VERSION ""

NS_ :

BS_:

BU_: DSC DME SZL

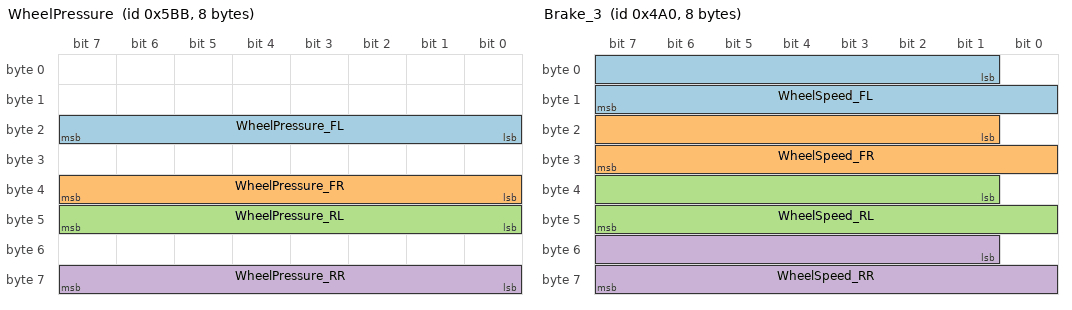
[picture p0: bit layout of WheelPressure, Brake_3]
BO_ 1467 WheelPressure: 8 DSC
 SG_ WheelPressure_FL : 16|8@1+ (1,0) [0|255] "bar" Vector__XXX
 SG_ WheelPressure_FR : 32|8@1+ (1,0) [0|255] "bar" Vector__XXX
 SG_ WheelPressure_RL : 40|8@1+ (1,0) [0|255] "bar" Vector__XXX
 SG_ WheelPressure_RR : 56|8@1+ (1,0) [0|255] "bar" Vector__XXX

BO_ 416 Brake_1: 8 DSC
 SG_ ASR_TrqReductionReq : 0|1@1+ (1,0) [0|1] "" Vector__XXX
 SG_ MSR_TrqIncreaseReq : 1|1@1+ (1,0) [0|1] "" Vector__XXX
 SG_ ABS_Active : 2|1@1+ (1,0) [0|1] "" Vector__XXX
 SG_ TCS_Active : 3|1@1+ (1,0) [0|1] "" Vector__XXX
 SG_ AYC_Active : 4|1@1+ (1,0) [0|1] "" Vector__XXX
 SG_ ASR_ActiveIndicator : 5|2@1+ (1,0) [0|3] "" Vector__XXX
 SG_ ABS_EBV_Running : 7|1@1+ (1,0) [0|1] "" Vector__XXX
 SG_ ABS_WarningLamp : 8|1@1+ (1,0) [0|1] "" Vector__XXX
 SG_ DSC_TCS_Lamp : 9|1@1+ (1,0) [0|1] "" Vector__XXX
 SG_ Brake_EBV_FailLamp : 10|1@1+ (1,0) [0|1] "" Vector__XXX
 SG_ BrakeLightSwitch : 11|1@1+ (1,0) [0|1] "" Vector__XXX
 SG_ DiagSessionBusy : 15|1@1+ (1,0) [0|1] "" Vector__XXX
 SG_ VehicleSpeed : 17|15@1+ (0.01,0) [0|327.67] "km/h" Vector__XXX
 SG_ ASR_TrqTarget : 32|8@1+ (0.39,0) [0|99.45] "%" Vector__XXX
 SG_ ASR_HoldTrq_MSR_Inv : 40|8@1+ (1,0) [0|255] "" Vector__XXX
 SG_ MSR_TrqTarget : 48|8@1+ (0.39,0) [0|99.45] "%" Vector__XXX
 SG_ AliveCounter : 56|4@1+ (1,0) [0|15] "" Vector__XXX
 SG_ DSC_SwitchModeA_0or6 : 61|1@1+ (1,0) [0|1] "" Vector__XXX
 SG_ LatchedFaultPresent : 62|1@1+ (1,0) [0|1] "" Vector__XXX
 SG_ ExtSpeedStatus : 63|1@1+ (1,0) [0|1] "" Vector__XXX

BO_ 428 Brake_8: 8 DSC
 SG_ LongitudinalAccel : 48|10@1+ (0.00408,-2.08896) [-2.08896|2.08488] "g" Vector__XXX

BO_ 1184 Brake_3: 8 DSC
 SG_ WheelSpeed_FL : 1|15@1+ (0.01,0) [0|327.67] "km/h" Vector__XXX
 SG_ WheelSpeed_FR : 17|15@1+ (0.01,0) [0|327.67] "km/h" Vector__XXX
 SG_ WheelSpeed_RL : 33|15@1+ (0.01,0) [0|327.67] "km/h" Vector__XXX
 SG_ WheelSpeed_RR : 49|15@1+ (0.01,0) [0|327.67] "km/h" Vector__XXX

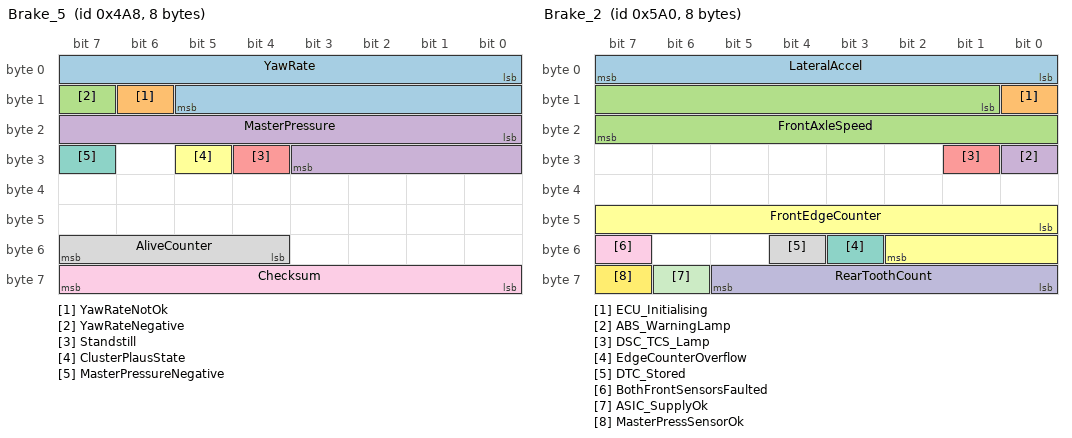
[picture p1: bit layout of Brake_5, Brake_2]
BO_ 1192 Brake_5: 8 DSC
 SG_ YawRate : 0|14@1+ (0.01,0) [0|163.83] "deg/s" Vector__XXX
 SG_ YawRateNotOk : 14|1@1+ (1,0) [0|1] "" Vector__XXX
 SG_ YawRateNegative : 15|1@1+ (1,0) [0|1] "" Vector__XXX
 SG_ MasterPressure : 16|12@1+ (0.1,0) [0|409.5] "bar" Vector__XXX
 SG_ Standstill : 28|1@1+ (1,0) [0|1] "" Vector__XXX
 SG_ ClusterPlausState : 29|1@1+ (1,0) [0|1] "" Vector__XXX
 SG_ MasterPressureNegative : 31|1@1+ (1,0) [0|1] "" Vector__XXX
 SG_ AliveCounter : 52|4@1+ (1,0) [0|15] "" Vector__XXX
 SG_ Checksum : 56|8@1+ (1,0) [0|255] "" Vector__XXX

BO_ 1440 Brake_2: 8 DSC
 SG_ LateralAccel : 0|8@1+ (0.02,-2.54) [-2.54|2.56] "g" Vector__XXX
 SG_ ECU_Initialising : 8|1@1+ (1,0) [0|1] "" Vector__XXX
 SG_ FrontAxleSpeed : 9|15@1+ (0.01,0) [0|327.67] "km/h" Vector__XXX
 SG_ ABS_WarningLamp : 24|1@1+ (1,0) [0|1] "" Vector__XXX
 SG_ DSC_TCS_Lamp : 25|1@1+ (1,0) [0|1] "" Vector__XXX
 SG_ FrontEdgeCounter : 40|11@1+ (1,0) [0|2047] "" Vector__XXX
 SG_ EdgeCounterOverflow : 51|1@1+ (1,0) [0|1] "" Vector__XXX
 SG_ DTC_Stored : 52|1@1+ (1,0) [0|1] "" Vector__XXX
 SG_ BothFrontSensorsFaulted : 55|1@1+ (1,0) [0|1] "" Vector__XXX
 SG_ RearToothCount : 56|6@1+ (1,0) [0|63] "" Vector__XXX
 SG_ ASIC_SupplyOk : 62|1@1+ (1,0) [0|1] "" Vector__XXX
 SG_ MasterPressSensorOk : 63|1@1+ (1,0) [0|1] "" Vector__XXX

BO_ 1696 CCP_DTO: 8 DSC
 SG_ DTO_Data : 0|64@1+ (1,0) [0|1.844674407e+19] "" Vector__XXX

BO_ 1986 Key_7C2: 4 DSC
 SG_ KeyStatusByte : 0|8@1+ (1,0) [0|255] "" Vector__XXX

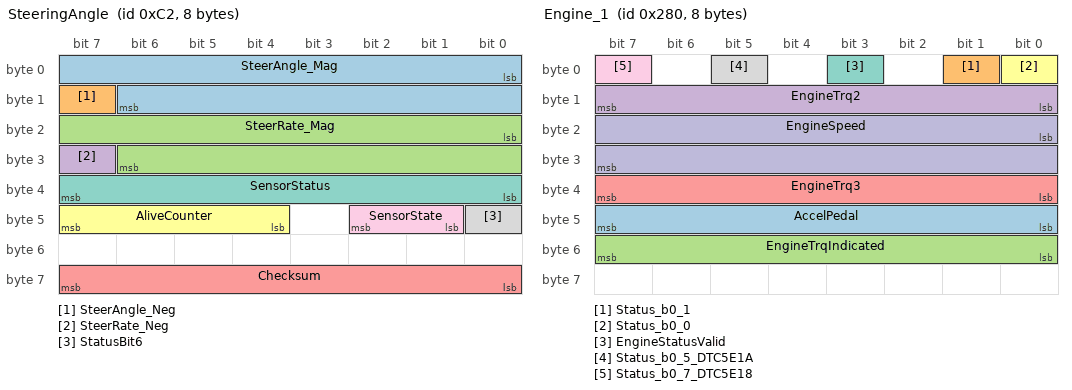
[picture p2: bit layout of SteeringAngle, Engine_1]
BO_ 194 SteeringAngle: 8 SZL
 SG_ SteerAngle_Mag : 0|15@1+ (1,0) [0|32767] "" DSC
 SG_ SteerAngle_Neg : 15|1@1+ (1,0) [0|1] "" DSC
 SG_ SteerRate_Mag : 16|15@1+ (1,0) [0|32767] "" DSC
 SG_ SteerRate_Neg : 31|1@1+ (1,0) [0|1] "" DSC
 SG_ Checksum : 56|8@1+ (1,0) [0|255] "" DSC
 SG_ AliveCounter : 44|4@1+ (1,0) [0|15] "" DSC
 SG_ SensorStatus : 32|8@1+ (1,0) [0|255] "" DSC
 SG_ StatusBit6 : 40|1@1+ (1,0) [0|1] "" DSC
 SG_ SensorState : 41|2@1+ (1,0) [0|3] "" DSC

BO_ 640 Engine_1: 8 DME
 SG_ AccelPedal : 40|8@1+ (1,0) [0|255] "" DSC
 SG_ Status_b0_1 : 1|1@1+ (1,0) [0|1] "" DSC
 SG_ EngineTrqIndicated : 48|8@1+ (1,0) [0|255] "" DSC
 SG_ EngineTrq2 : 8|8@1+ (1,0) [0|255] "" DSC
 SG_ EngineTrq3 : 32|8@1+ (1,0) [0|255] "" DSC
 SG_ Status_b0_0 : 0|1@1+ (1,0) [0|1] "" DSC
 SG_ EngineStatusValid : 3|1@1+ (1,0) [0|1] "" DSC
 SG_ Status_b0_5_DTC5E1A : 5|1@1+ (1,0) [0|1] "" DSC
 SG_ Status_b0_7_DTC5E18 : 7|1@1+ (1,0) [0|1] "" DSC
 SG_ EngineSpeed : 16|16@1+ (0.5,0) [0|32767.5] "rpm" DSC

BO_ 648 Engine_2: 8 DME
 SG_ MaxTrqScale : 0|8@1+ (1,0) [0|255] "" DSC
 SG_ Status_b2_4 : 20|1@1+ (1,0) [0|1] "" DSC

BO_ 704 Diag_2C0: 4 Vector__XXX
 SG_ Byte1_DTC5E58 : 8|8@1+ (1,0) [0|255] "" DSC

BO_ 912 BrakeMode_390: 8 Vector__XXX
 SG_ BrakeMode1 : 50|1@1+ (1,0) [0|1] "" DSC
 SG_ BrakeMode3 : 51|1@1+ (1,0) [0|1] "" DSC

BO_ 1088 Gear_440: 8 Vector__XXX
 SG_ GearSourceFlag : 0|1@1+ (1,0) [0|1] "" DSC
 SG_ GearCode : 8|4@1+ (1,0) [0|15] "" DSC

BO_ 1152 Engine_3: 8 DME
 SG_ TrqScaleMultiplierSel : 51|1@1+ (1,0) [0|1] "" DSC

BO_ 1312 Odometer_520: 8 Vector__XXX
 SG_ Value14_Mode2 : 0|16@1+ (1,0) [0|65535] "" DSC
 SG_ Odometer : 40|20@1+ (1,0) [0|1048575] "" DSC

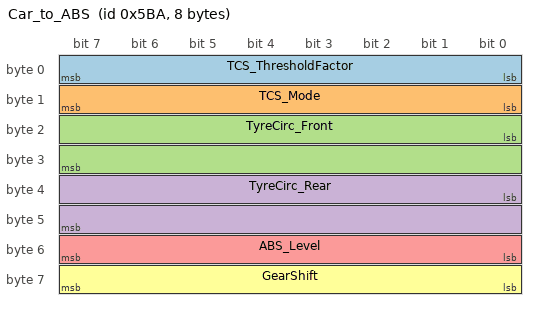
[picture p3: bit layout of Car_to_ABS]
BO_ 1466 Car_to_ABS: 8 Vector__XXX
 SG_ TCS_ThresholdFactor : 0|8@1+ (1,0) [0|255] "%" DSC
 SG_ TCS_Mode : 8|8@1+ (1,0) [0|255] "" DSC
 SG_ TyreCirc_Front : 16|16@1+ (1,0) [0|65535] "mm" DSC
 SG_ TyreCirc_Rear : 32|16@1+ (1,0) [0|65535] "mm" DSC
 SG_ ABS_Level : 48|8@1+ (1,0) [0|255] "" DSC
 SG_ GearShift : 56|8@1+ (1,0) [0|255] "" DSC

BO_ 1490 KeyHandshake: 8 Vector__XXX
 SG_ Mode : 0|2@1+ (1,0) [0|3] "" DSC
 SG_ Key : 32|32@1+ (1,0) [0|4294967295] "" DSC

BO_ 1500 Diag_5DC: 8 Vector__XXX
 SG_ Bit_b1_1_DTC5E58 : 9|1@1+ (1,0) [0|1] "" DSC

BO_ 1698 CCP_CRO: 8 Vector__XXX
 SG_ CRO_Data : 0|64@1+ (1,0) [0|1.844674407e+19] "" DSC

CM_ "Z4 GT3 ABS/DSC module (Continental MK60E5 / DSC60, software ZB 6769162). Derived from analysis of the module software. Node DSC = this module. Only fields the software computes or uses are included; received fields it ignores and transmitted fields with a fixed value are left out. Scaling is given where it is established; other fields are raw. Byte/bit numbering 0-based, little-endian (Intel). Fault references are the DTC numbers the module reports over KWP $18. Bus: main (vehicle) CAN.";
CM_ BO_ 1698 "CCP command receive object (CRO). Commands are handled only in diagnostic state 4 (entered with KWP $31 $31). Received by this module, event-driven.";
CM_ BO_ 1500 "Not in the Continental document. One bit reports DTC 0x5E58; any reception reloads a watchdog. Avoid sending it. Received by this module, event-driven. Receive-timeout reference 50 (age-counter units).";
CM_ BO_ 1490 "Identification/key handshake: a 32-bit key is compared with the stored key (stored when it differs). Completed by 0x7C2.";
CM_ BO_ 1466 "Car -> ABS configuration (Continental document: 'Car -> ABS', 1000 ms). TCS threshold factor and mode, front/rear tyre circumference, ABS level (knob) and gear-shift-in-progress. All used. On timeout (reception reloads a counter to 9) every value becomes 0xFF: tyre circumference falls back to the flash defaults, ABS level to off, gear-shift suppression is cleared, TCS mode is flagged invalid. Received by this module, every 1000 ms. Receive-timeout reference 50 (age-counter units).";
CM_ BO_ 1312 "Not in the Continental document. Odometer (bytes 5-7), used only as the mileage stored with each DTC; a 14-bit value and 2-bit mode are stored but have no direct reader (mode 3 without the front-speed flag raises DTC 0x5E16). Received by this module, event-driven. Receive-timeout reference 200 (age-counter units).";
CM_ BO_ 1152 "Engine ECU frame 3; not in the Continental document. One bit selects the torque-scale multiplier used with 0x288; the other fields are stored but never read. Received by this module, event-driven. Receive-timeout reference 50 (age-counter units).";
CM_ BO_ 1088 "Gear position (with a source flag); not in the Continental document. Used by AYC, hill-hold and the TCS oscillation limiter. Other fields ignored. Received by this module, event-driven. Receive-timeout reference 50 (age-counter units).";
CM_ BO_ 912 "Not in the Continental document. Two bits select a brake-function mode (brake-assist pedal scaling / pressure arbiter); everything else is ignored. Received by this module, event-driven. Receive-timeout reference 50 (age-counter units).";
CM_ BO_ 704 "Not in the Continental document. Receiving this frame does nothing except report DTC 0x5E58. Avoid sending it. Received by this module, event-driven. Receive-timeout reference 50 (age-counter units).";
CM_ BO_ 648 "Engine ECU (DME) frame 2; not in the Continental document. Supplies the maximum-torque scaling for the 0x280 torque values; the other fields are ignored. On timeout the torque values are marked invalid while the scale is not yet known. Received by this module, event-driven. Receive-timeout reference 50 (age-counter units).";
CM_ BO_ 640 "Engine ECU (DME) frame 1; not in the Continental document. Accelerator pedal, three engine-torque values, engine speed and status bits. Used by TCS/ASR/MSR, hill-hold, AYC, brake assist and the ABS classifier. On timeout (more than 10 counts) the engine values are marked invalid. Received by this module, event-driven. Receive-timeout reference 50 (age-counter units).";
CM_ BO_ 194 "Steering angle sensor (SZL) on the main CAN; not in the Continental document. Angle and angle rate (sign-magnitude), sensor status, alive counter, checksum. The SZL is needed for yaw/ay to be trusted (steering verification). A timeout has no effect: the last angle is kept and its trust is unchanged. Received by this module, event-driven. Receive-timeout reference 11 (age-counter units).";
CM_ BO_ 1986 "Not in the Continental document. Part of an identification/key handshake with 0x5D2: one status byte, bytes 1-3 always 0. The same ID is also received (4 bytes): a reception after a 0x5D2 key completes the handshake (store request); its content is not decoded. A DBC holds one message per ID, so only the TX layout is given. Sent by this module, event-driven.";
CM_ BO_ 1696 "CCP data transmission object (DTO): replies to CCP commands and DAQ (measurement) lists 0-4. Only active once a CCP session is open (KWP $31 $31 enters diagnostic state 4). Sent by this module, event-driven.";
CM_ BO_ 1440 "Brake 2 (Continental document: 'Brake 2', 20 ms). Lateral acceleration, ABS and DSC lamps, front-axle mean speed, a front wheel-sensor edge counter (distance pulses) and sensor/DTC status bits. Sent by this module, every 20 ms.";
CM_ BO_ 1192 "Brake 5 (Continental document: 'Brake 5', 20 ms). Yaw rate (magnitude + sign), master-cylinder brake pressure (magnitude + sign), standstill flag. Alive counter (byte 6 high nibble) and XOR checksum (byte 7) are not in the Continental document. Sent by this module, every 20 ms.";
CM_ BO_ 1184 "Brake 3 (Continental document: 'Brake 3', 10 ms). The four wheel speeds. The bit in front of each speed is always 0 (the M3's direction bits are not filled). Sent by this module, every 10 ms.";
CM_ BO_ 428 "Brake 8 (Continental document: 'Brake 8', 20 ms). Longitudinal acceleration. Sent by this module, every 20 ms.";
CM_ BO_ 416 "Brake 1 (Continental document: 'Brake 1', 10 ms). Main ABS/DSC status frame: which control is active (ABS, TCS, AYC, ASR/MSR), the three warning lamps, brake light switch, vehicle speed, and the ASR/MSR engine-torque requests to the engine ECU (this firmware has no separate torque-request message). Alive counter in byte 7. Sent by this module, every 10 ms.";
CM_ BO_ 1467 "Wheel brake pressures (Continental document: wheel pressures, 20 ms). Four channels in whole bar; the other bytes are 0. Sent by this module, every 20 ms.";
CM_ SG_ 1467 WheelPressure_FL "Wheel pressure channel 0, whole bar (0.01 bar / 100), clamped to 0xFE; 0xFF sensor invalid.";
CM_ SG_ 1467 WheelPressure_FR "Wheel pressure channel 1.";
CM_ SG_ 1467 WheelPressure_RL "Wheel pressure channel 2.";
CM_ SG_ 1467 WheelPressure_RR "Wheel pressure channel 3.";
CM_ SG_ 416 ASR_TrqReductionReq "1 = traction control (ASR) or AYC is asking the engine to reduce torque.";
CM_ SG_ 416 MSR_TrqIncreaseReq "1 = engine drag-torque control (MSR) is asking the engine to raise torque (prevents driven-wheel lock on lift-off/downshift).";
CM_ SG_ 416 ABS_Active "1 = ABS is controlling at least one wheel.";
CM_ SG_ 416 TCS_Active "1 = traction control is braking a wheel.";
CM_ SG_ 416 AYC_Active "1 = yaw-stability control (AYC) is active. Needs valid yaw, ay and steering.";
CM_ SG_ 416 ASR_ActiveIndicator "ASR intervention indicator for the cluster (3 = active).";
CM_ SG_ 416 ABS_EBV_Running "1 = ABS/EBV (brake-force distribution) control is running.";
CM_ SG_ 416 ABS_WarningLamp "ABS warning lamp request.";
CM_ SG_ 416 DSC_TCS_Lamp "DSC/TCS indicator lamp request.";
CM_ SG_ 416 Brake_EBV_FailLamp "Brake / EBV failure lamp request.";
CM_ SG_ 416 BrakeLightSwitch "Brake light switch pressed (switch only; no pressure term).";
CM_ SG_ 416 DiagSessionBusy "1 = a diagnostic/manufacturing session is open.";
CM_ SG_ 416 VehicleSpeed "Vehicle speed: the ABS reference speed while ABS/MSR is active (and 20 cycles after), otherwise the mean of the healthy front wheels.";
CM_ SG_ 416 ASR_TrqTarget "ASR torque-reduction target as % of maximum engine torque.";
CM_ SG_ 416 ASR_HoldTrq_MSR_Inv "ASR: second (hold) torque target; MSR: inverted MSR value.";
CM_ SG_ 416 MSR_TrqTarget "MSR torque-increase target as % of maximum engine torque.";
CM_ SG_ 416 AliveCounter "Alive counter 0..15, incremented every frame.";
CM_ SG_ 416 DSC_SwitchModeA_0or6 "DSC switch mode A is 0 or 6.";
CM_ SG_ 416 LatchedFaultPresent "1 = a latched fault is present.";
CM_ SG_ 416 ExtSpeedStatus "External speed status (front speed invalid / speed source flag).";
CM_ SG_ 428 LongitudinalAccel "Longitudinal acceleration from the sensor cluster, offset-corrected.";
CM_ SG_ 1184 WheelSpeed_FL "Front-left wheel speed. 0 below the standstill floor.";
CM_ SG_ 1184 WheelSpeed_FR "Front-right wheel speed.";
CM_ SG_ 1184 WheelSpeed_RL "Rear-left wheel speed.";
CM_ SG_ 1184 WheelSpeed_RR "Rear-right wheel speed.";
CM_ SG_ 1192 YawRate "Yaw rate magnitude (sign in YawRateNegative). 0 while the ECU initialises.";
CM_ SG_ 1192 YawRateNotOk "1 = yaw rate not usable (sensor cluster held, ECU initialising, or yaw marked invalid, e.g. steering uncalibrated).";
CM_ SG_ 1192 YawRateNegative "Yaw rate sign: 1 = negative.";
CM_ SG_ 1192 MasterPressure "Master-cylinder brake pressure magnitude (sign in MasterPressureNegative).";
CM_ SG_ 1192 Standstill "1 = all four wheels below the standstill speed.";
CM_ SG_ 1192 ClusterPlausState "Sensor-cluster plausibility state bit.";
CM_ SG_ 1192 MasterPressureNegative "Master pressure sign: 1 = negative.";
CM_ SG_ 1192 AliveCounter "Alive counter 0..15.";
CM_ SG_ 1192 Checksum "XOR of bytes 0..6.";
CM_ SG_ 1440 LateralAccel "Lateral acceleration, offset-corrected.";
CM_ SG_ 1440 ECU_Initialising "1 = ECU initialising.";
CM_ SG_ 1440 FrontAxleSpeed "Mean speed of the healthy front wheels.";
CM_ SG_ 1440 ABS_WarningLamp "ABS warning lamp request (same as Brake_1).";
CM_ SG_ 1440 DSC_TCS_Lamp "DSC/TCS indicator lamp request (same as Brake_1).";
CM_ SG_ 1440 FrontEdgeCounter "Front wheel-sensor edge counter (distance pulses), wraps at 11 bits.";
CM_ SG_ 1440 EdgeCounterOverflow "Edge counter overflowed.";
CM_ SG_ 1440 DTC_Stored "1 = at least one DTC is stored.";
CM_ SG_ 1440 BothFrontSensorsFaulted "1 = both front wheel-speed sensors are faulted.";
CM_ SG_ 1440 RearToothCount "Rear tone-wheel tooth count.";
CM_ SG_ 1440 ASIC_SupplyOk "1 = valve/pump driver ASIC supply ok.";
CM_ SG_ 1440 MasterPressSensorOk "1 = master pressure sensor ok.";
CM_ SG_ 1696 DTO_Data "CCP DTO: command return and DAQ lists 0-4 (six table records share this ID).";
CM_ SG_ 1986 KeyStatusByte "Key-handshake status byte.";
CM_ SG_ 194 SteerAngle_Mag "Steering angle magnitude (sign-magnitude 16-bit field, 0x8000 = invalid). Degree scaling not established.";
CM_ SG_ 194 SteerAngle_Neg "Steering angle sign (1 = negative).";
CM_ SG_ 194 SteerRate_Mag "Steering angle rate magnitude (sign-magnitude, 0x8000 = invalid).";
CM_ SG_ 194 SteerRate_Neg "Steering angle rate sign (1 = negative).";
CM_ SG_ 194 Checksum "Checksum: ~(byte0+byte1+byte2+byte3+byte5) must equal this byte; a bad checksum raises DTC 0x5E43.";
CM_ SG_ 194 AliveCounter "Alive counter; 4 equal values in a row raise DTC 0x5E1E (yaw/ay/steering invalid).";
CM_ SG_ 194 SensorStatus "Sensor status; bit 7 = sensor initialised (needed for steering calibration and trust).";
CM_ SG_ 194 StatusBit6 "Status bit; influences the steering state machine.";
CM_ SG_ 194 SensorState "2-bit sensor state; 3 = sensor fault (raises DTC 0x5E43).";
CM_ SG_ 640 AccelPedal "Accelerator pedal position (raw; 0xFF = invalid, last value kept).";
CM_ SG_ 640 Status_b0_1 "Engine status bit; also marks pedal/torque invalid.";
CM_ SG_ 640 EngineTrqIndicated "Indicated engine torque (raw, scaled by the 0x288 max-torque factor; 0xFF = invalid).";
CM_ SG_ 640 EngineTrq2 "Engine torque value 2 (raw, same scaling).";
CM_ SG_ 640 EngineTrq3 "Engine torque value 3 (raw, same scaling).";
CM_ SG_ 640 Status_b0_0 "Engine status bit; feeds the CAN application cycle and the engine interface.";
CM_ SG_ 640 EngineStatusValid "Engine status valid (0 = engine status invalid).";
CM_ SG_ 640 Status_b0_5_DTC5E1A "Status bit; 1 raises DTC 0x5E1A.";
CM_ SG_ 640 Status_b0_7_DTC5E18 "Status bit; 1 raises DTC 0x5E18, 0 reloads the engine-message watchdog.";
CM_ SG_ 640 EngineSpeed "Engine speed (sent as rpm x 2). Above 0xFEFF = invalid (DTC 0x5E1A).";
CM_ SG_ 648 MaxTrqScale "Maximum-torque scale for the 0x280 torque values.";
CM_ SG_ 648 Status_b2_4 "Engine status bit (stored engine-interface flag).";
CM_ SG_ 704 Byte1_DTC5E58 "Any reception raises DTC 0x5E58.";
CM_ SG_ 912 BrakeMode1 "1 = brake-function mode 1.";
CM_ SG_ 912 BrakeMode3 "1 = brake-function mode 3.";
CM_ SG_ 1088 GearSourceFlag "Gear-signal source flag (can raise DTC 0x5E19).";
CM_ SG_ 1088 GearCode "Gear code (6..9 remapped, 15 = invalid).";
CM_ SG_ 1152 TrqScaleMultiplierSel "Selects the torque-scale multiplier (1 or 2) used with 0x288.";
CM_ SG_ 1312 Value14_Mode2 "14-bit value and 2-bit mode, stored without a direct reader; mode 2 marks the front speed valid, mode 3 without it raises DTC 0x5E16.";
CM_ SG_ 1312 Odometer "Odometer; stored /10 as the mileage of each DTC record.";
CM_ SG_ 1466 TCS_ThresholdFactor "TCS slip threshold factor; used clamped to 30..250 %.";
CM_ SG_ 1466 TCS_Mode "TCS mode; other values are flagged invalid. Feeds the DSC mode request.";
CM_ SG_ 1466 TyreCirc_Front "Front tyre circumference; accepted only 1440..2880 mm and near standstill, otherwise the built-in default is used.";
CM_ SG_ 1466 TyreCirc_Rear "Rear tyre circumference; as front.";
CM_ SG_ 1466 ABS_Level "ABS level 0..9 (0 = max, 9..1 decreasing): levels 1..9 raise the wheel-deceleration dump threshold base by 0.05 g per step, saturating at level 4 with this calibration.";
CM_ SG_ 1466 GearShift "Gear shift in progress: each 0 -> non-zero edge suppresses rear ABS entry for about 150 ms.";
CM_ SG_ 1490 Mode "When 2, Key is compared with the stored key (identification handshake).";
CM_ SG_ 1490 Key "32-bit key; compared with the stored key, stored when it differs.";
CM_ SG_ 1500 Bit_b1_1_DTC5E58 "1 raises DTC 0x5E58.";
CM_ SG_ 1698 CRO_Data "CCP CRO, handled only in diagnostic state 4 (KWP $31 $31).";

BA_DEF_ BO_ "GenMsgCycleTime" INT 0 65535;
BA_DEF_DEF_ "GenMsgCycleTime" 0;
BA_ "GenMsgCycleTime" BO_ 1467 20;
BA_ "GenMsgCycleTime" BO_ 416 10;
BA_ "GenMsgCycleTime" BO_ 428 20;
BA_ "GenMsgCycleTime" BO_ 1184 10;
BA_ "GenMsgCycleTime" BO_ 1192 20;
BA_ "GenMsgCycleTime" BO_ 1440 20;
BA_ "GenMsgCycleTime" BO_ 1466 1000;

VAL_ 1467 WheelPressure_FL 254 "Clamp" 255 "Invalid" ;
VAL_ 1467 WheelPressure_FR 254 "Clamp" 255 "Invalid" ;
VAL_ 1467 WheelPressure_RL 254 "Clamp" 255 "Invalid" ;
VAL_ 1467 WheelPressure_RR 254 "Clamp" 255 "Invalid" ;
VAL_ 416 VehicleSpeed 32725 "SensorFault" 32742 "SensorFault2" ;
VAL_ 416 ASR_TrqTarget 254 "NoRequest" 255 "BothRequests" ;
VAL_ 416 ASR_HoldTrq_MSR_Inv 254 "Idle" 255 "BothRequests" ;
VAL_ 416 MSR_TrqTarget 255 "BothRequests" ;
VAL_ 428 LongitudinalAccel 1023 "Invalid" ;
VAL_ 1184 WheelSpeed_FL 32725 "SensorFault" 32742 "SensorFault2" ;
VAL_ 1184 WheelSpeed_FR 32725 "SensorFault" 32742 "SensorFault2" ;
VAL_ 1184 WheelSpeed_RL 32725 "SensorFault" 32742 "SensorFault2" ;
VAL_ 1184 WheelSpeed_RR 32725 "SensorFault" 32742 "SensorFault2" ;
VAL_ 1192 MasterPressure 4095 "Invalid" ;
VAL_ 1440 FrontAxleSpeed 32725 "Invalid" 32742 "Invalid2" ;
VAL_ 194 SensorState 0 "OK" 1 "Class1" 2 "Class1b" 3 "Fault" ;
VAL_ 640 AccelPedal 255 "Invalid" ;
VAL_ 640 EngineTrqIndicated 255 "Invalid" ;
VAL_ 640 EngineTrq2 255 "Invalid" ;
VAL_ 640 EngineTrq3 255 "Invalid" ;
VAL_ 1088 GearCode 15 "Invalid" ;
VAL_ 1312 Odometer 1048575 "Invalid" ;
VAL_ 1466 TCS_Mode 0 "Off" 1 "HighBase" 2 "LowBase" ;
VAL_ 1466 ABS_Level 0 "Max" 1 "Min" 255 "Timeout" ;
VAL_ 1466 GearShift 0 "None" 1 "Up" 2 "Down" ;
